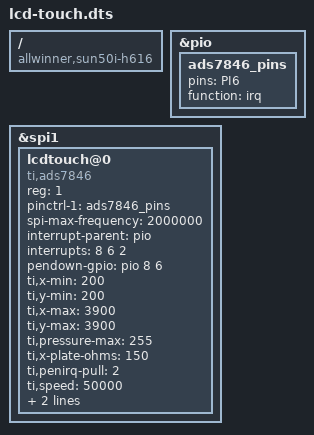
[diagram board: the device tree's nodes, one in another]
/dts-v1/;
/plugin/;

/ {
	compatible = "allwinner,sun50i-h616";

	fragment@0 {
		target = <&pio>;
		__overlay__ {
			ads7846_pins: ads7846_pins {
				pins = "PI6";
				function = "irq";
			};
		};
	};

	fragment@1 {
		target = <&spi1>;
		__overlay__ {
			status = "okay";
			lcdtouch@0 {
				compatible = "ti,ads7846";
				reg = <1>; /* Chip Select 1 */
				status = "okay";
				pinctrl-names = "default", "lcdtouchctrl";
				pinctrl-1 = <&ads7846_pins>;
				spi-max-frequency = <2000000>;
				interrupt-parent = <&pio>;
				interrupts = <8 6 2>; /* PI6 IRQ_TYPE_EDGE_FALLING */
				pendown-gpio = <&pio 8 6 0>; /* PI6 */

				/* driver defaults, optional */
				ti,x-min = /bits/ 16 <200>;
				ti,y-min = /bits/ 16 <200>;
				ti,x-max = /bits/ 16 <3900>;
				ti,y-max = /bits/ 16 <3900>;
				ti,pressure-max = /bits/ 16 <255>;
				ti,x-plate-ohms = /bits/ 16 <150>;
				ti,penirq-pull = /bits/ 16 <2>;
				ti,speed = /bits/ 16 <50000>;
				ti,keep-vref-on = /bits/ 16 <0>;
				ti,swap-xy = /bits/ 16 <0>;
			};
		};
	};
};
